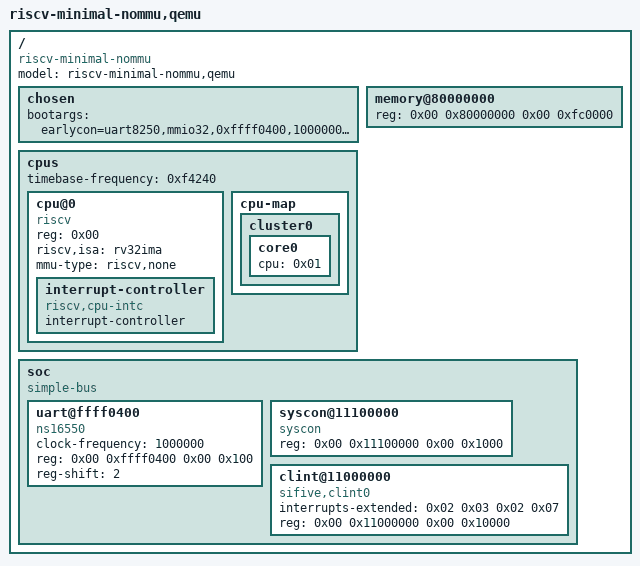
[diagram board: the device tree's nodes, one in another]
/dts-v1/;

/ {
	#address-cells = <0x02>;
	#size-cells = <0x02>;
	compatible = "riscv-minimal-nommu";
	model = "riscv-minimal-nommu,qemu";

	chosen {
		bootargs = "earlycon=uart8250,mmio32,0xffff0400,1000000 console=ttyS0";
	};

	memory@80000000 {
		device_type = "memory";
		reg = <0x00 0x80000000 0x00 0xfc0000>;
	};

	cpus {
		#address-cells = <0x01>;
		#size-cells = <0x00>;
		timebase-frequency = <0xf4240>;

		cpu@0 {
			phandle = <0x01>;
			device_type = "cpu";
			reg = <0x00>;
			status = "okay";
			compatible = "riscv";
			riscv,isa = "rv32ima";
			mmu-type = "riscv,none";

			interrupt-controller {
				#interrupt-cells = <0x01>;
				interrupt-controller;
				compatible = "riscv,cpu-intc";
				phandle = <0x02>;
			};
		};

		cpu-map {

			cluster0 {

				core0 {
					cpu = <0x01>;
				};
			};
		};
	};

	soc {
		#address-cells = <0x02>;
		#size-cells = <0x02>;
		compatible = "simple-bus";
		ranges;

		uart@ffff0400 {
			clock-frequency = <1000000>;
			reg = <0x00 0xffff0400 0x00 0x100>;
			reg-shift = <2>;
			compatible = "ns16550";
		};

		syscon@11100000 {
			phandle = <0x04>;
			reg = <0x00 0x11100000 0x00 0x1000>;
			compatible = "syscon";
		};

		clint@11000000 {
			interrupts-extended = <0x02 0x03 0x02 0x07>;
			reg = <0x00 0x11000000 0x00 0x10000>;
			compatible = "sifive,clint0\0riscv,clint0";
		};
	};
};
